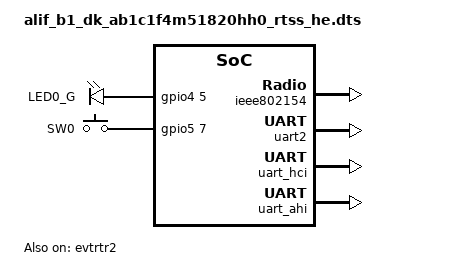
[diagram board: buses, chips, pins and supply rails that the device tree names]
/* Copyright (c) 2025 Alif Semiconductor
 *
 * SPDX-License-Identifier: Apache-2.0
 */

/dts-v1/;

#include <alif/balletto/b1/ab1c1f4m51820hh0.dtsi>
#include "../common/balletto-pinctrl.dtsi"

/* Enable to use Event Router driver instead of manual configuration
 * When enabled:
 * - DMA routing goes through event router driver
 * - Manual event router configuration is disabled
 * When disabled:
 * - Direct DMA approach with manual event router programming
 */
#define USE_EVENT_ROUTER_DRIVER   1

#if USE_EVENT_ROUTER_DRIVER
#include <zephyr/dt-bindings/dma/alif_dma.h>
#endif

/ {
	compatible = "arm,alif-b1-dk-ab1c1f4m51820hh0-rtss-he";
	#address-cells = <1>;
	#size-cells = <1>;
};

&ieee802154 {
	status = "okay";
};

&{/} {
	chosen {
		zephyr,console = &uart2;
		zephyr,shell-uart = &uart2;
		zephyr,bt-hci = &alif_hci_uart;
		zephyr,hci-uart = &uart_hci;
		zephyr,uart-mcumgr = &uart2;
		zephyr,entropy = &rng;
	};

	aliases {
		led0 = &aled0;
		sw0 = &button0;
		watchdog0 = &wdog0;
	};

	leds {
		compatible = "gpio-leds";

		aled0: led_0 {
			gpios = <&gpio4 5 0>;
			label = "LED0_G";
		};
	};

	buttons {
		compatible = "gpio-keys";

		button0: button_0 {
			gpios = < &gpio5 7 0 >;
			label = "SW0";
		};
	};
};

&uart2 {
	status = "okay";
};

#if USE_EVENT_ROUTER_DRIVER
/* Event Router driver approach: route through event router */

&evtrtr2 {
	status = "okay";
};

&uart_hci {
	/*
	 * Cell 0: ALIF_DMA_ENCODE(channel, dma_group, handshake)
	 *   - channel: Physical DMA channel (0 for RX, 1 for TX)
	 *   - dma_group: Input source selection (0) - selects which peripheral input
	 *   - handshake: Enable hardware handshaking (1 for UART)
	 * Cell 1: Peripheral request number (26 for RX, 27 for TX)
	 */
	dmas = <&evtrtr2 ALIF_DMA_ENCODE(HCI_UART_DMA_RX_CH, 0, 1) HCI_UART_DMA_RX_REQ>,
	       <&evtrtr2 ALIF_DMA_ENCODE(HCI_UART_DMA_TX_CH, 0, 1) HCI_UART_DMA_TX_REQ>;
	dma-names = "rx", "tx";
	status = "okay";
};

&uart_ahi {
	pinctrl-0 = <&pinctrl_ahi_trace>;
	pinctrl-names = "default";
	/*
	 * Cell 0: ALIF_DMA_ENCODE(channel, dma_group, handshake)
	 *   - channel: Physical DMA channel (2 for RX, 3 for TX)
	 *   - dma_group: Input source selection (0) - selects which peripheral input
	 *   - handshake: Enable hardware handshaking (1 for UART)
	 * Cell 1: Peripheral request number (2 for RX, 3 for TX)
	 */
	dmas = <&evtrtr2 ALIF_DMA_ENCODE(AHI_UART_DMA_RX_CH, 0, 1) AHI_UART_DMA_RX_REQ>,
	       <&evtrtr2 ALIF_DMA_ENCODE(AHI_UART_DMA_TX_CH, 0, 1) AHI_UART_DMA_TX_REQ>;
	dma-names = "rx", "tx";
	status = "okay";
};

#else
/* Direct DMA approach: manual event router configuration */

&uart_hci {
	/* Direct PL330 DMA specifier format:
	 * Cell 0: PL330 physical channel (0 for RX, 1 for TX)
	 * Cell 1: PL330 peripheral request (26 for RX, 27 for TX)
	 * Note: Event router must be manually configured
	 */
	dmas = <&dma2 HCI_UART_DMA_RX_CH HCI_UART_DMA_RX_REQ>,
	       <&dma2 HCI_UART_DMA_TX_CH HCI_UART_DMA_TX_REQ>;
	dma-names = "rx", "tx";
	status = "okay";
};

&uart_ahi {
	pinctrl-0 = <&pinctrl_ahi_trace>;
	pinctrl-names = "default";
	/* Direct PL330 DMA specifier format:
	 * Cell 0: PL330 physical channel (2 for RX, 3 for TX)
	 * Cell 1: PL330 peripheral request (2 for RX, 3 for TX)
	 * Note: Event router must be manually configured
	 */
	dmas = <&dma2 AHI_UART_DMA_RX_CH AHI_UART_DMA_RX_REQ>,
	       <&dma2 AHI_UART_DMA_TX_CH AHI_UART_DMA_TX_REQ>;
	dma-names = "rx", "tx";
	status = "okay";
};

#endif /* USE_EVENT_ROUTER_DRIVER */

&dma2 {
	status = "okay";
};

&gpio4 {
	status = "okay";
};

&gpio5 {
	status = "okay";
};
